# STM32N657 register map
File version: 1.0
CPU: CM55 r0p1, little endian, no MPU, FPU, vendor SysTick, 8 interrupt priority bits
Registers are 32-bit, read-write, reset 0x0 unless marked. A register's access mark holds for its fields unless they carry their own. Offsets are from the block's base; [hi:lo] are bit positions; 'fields as' and 'values as' point back to an identical list.

## LTDC — LCD-TFT display controller
Base 0x48001000
Same registers: LTDC_S 0x58001000
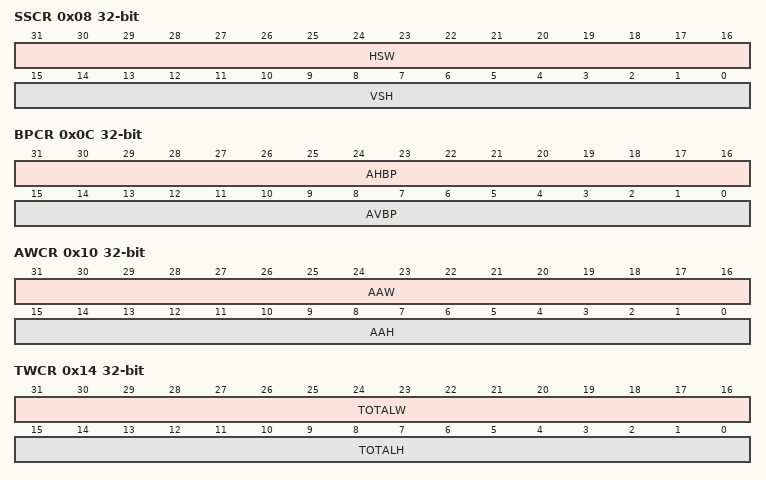
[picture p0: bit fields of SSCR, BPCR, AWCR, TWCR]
0x08 SSCR — LTDC synchronization size configuration register
  [31:16] HSW — horizontal synchronization width (in units of pixel clock period)
  [15:0] VSH — vertical synchronization height (in units of horizontal scan line)
0x0C BPCR — LTDC back porch configuration register
  [31:16] AHBP — accumulated horizontal back porch (in units of pixel clock period)
  [15:0] AVBP — accumulated Vertical back porch (in units of horizontal scan line)
0x10 AWCR — LTDC active width configuration register
  [31:16] AAW — accumulated active width (in units of pixel clock period)
  [15:0] AAH — accumulated active height (in units of horizontal scan line)
0x14 TWCR — LTDC total width configuration register
  [31:16] TOTALW — total width (in units of pixel clock period)
  [15:0] TOTALH — total height (in units of horizontal scan line)
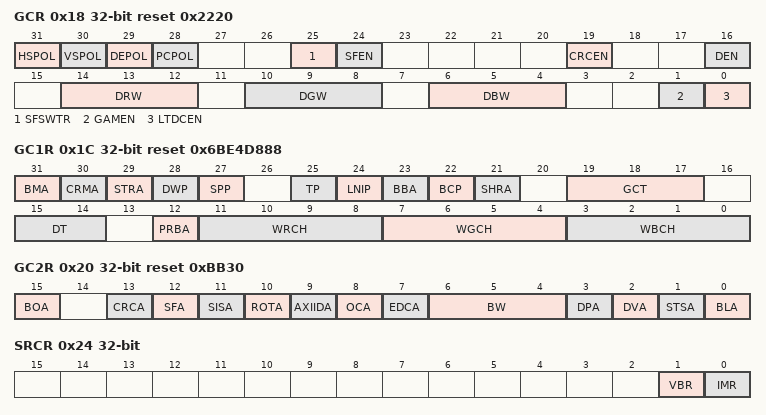
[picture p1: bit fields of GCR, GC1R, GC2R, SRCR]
0x18 GCR access per field reset 0x2220 — LTDC global control register
  [31] HSPOL rw — horizontal synchronization polarity
  [30] VSPOL rw — vertical synchronization polarity
  [29] DEPOL rw — blanking (no data/pixel) polarity
  [28] PCPOL rw — pixel clock polarity
  [25] SFSWTR wo — single-frame mode: software trigger
  [24] SFEN rw — single-frame mode: mode enable
  [19] CRCEN rw — CRC enable
  [16] DEN rw — dither enable
  [14:12] DRW ro — dither red width
  [10:8] DGW ro — dither green width
  [6:4] DBW ro — dither blue width
  [1] GAMEN rw — Gamma correction enable
  [0] LTDCEN rw — LTDC global enable
0x1C GC1R ro reset 0x6BE4D888 — LTDC global configuration 1 register
  [31] BMA — blind mode ability
  [30] CRMA — configuration reading mode ability
  [29] STRA — status register ability
  [28] DWP — dither width programmability
  [27] SPP — sync polarity programmability
  [25] TP — timing programmability
  [24] LNIP — line-IRQ: line position programmability
  [23] BBA — background blending ability
  [22] BCP — background color programmability (unique color blended as background)
  [21] SHRA — shadow registers ability
  [19:17] GCT — gamma correction technique implemented
  [15:14] DT — dithering technique implemented
  [12] PRBA — precise blending ability
  [11:8] WRCH — width of red channel output
  [7:4] WGCH — width of green channel output
  [3:0] WBCH — width of blue channel output
0x20 GC2R ro reset 0xBB30 — LTDC global configuration 2 register
  [15] BOA — blending order ability
  [13] CRCA — CRC ability
  [12] SFA — single frame mode ability
  [11] SISA — second interrupt set ability
  [10] ROTA — rotation support ability
  [9] AXIIDA — AXIID ability
  [8] OCA — output conversion ability (RGB to YCbCr)
  [7] EDCA — external display control ability
  [6:4] BW — bus width (log2 of number of bytes)
  [3] DPA — secondary RGB output port ability
  [2] DVA — dual-view ability
  [1] STSA — slave timings synchronization ability
  [0] BLA — background layer ability (pixels of background layer are read from memory)
0x24 SRCR — LTDC shadow reload configuration register
  [1] VBR — vertical blanking reload request
  [0] IMR — immediate reload trigger
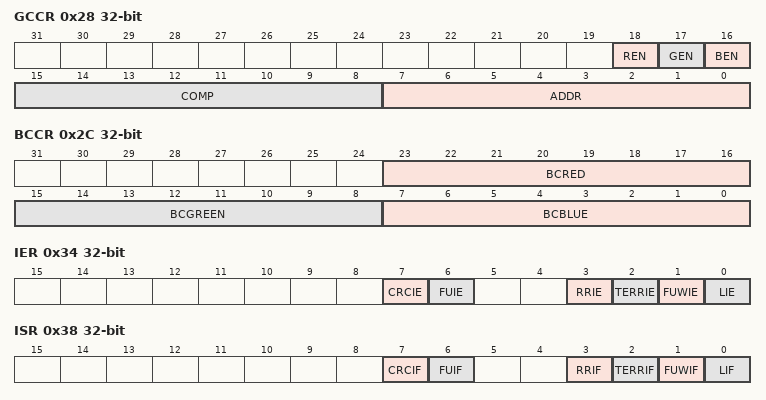
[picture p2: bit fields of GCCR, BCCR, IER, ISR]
0x28 GCCR wo — LTDC gamma correction configuration register
  [18] REN — write trigger to the red table
  [17] GEN — write trigger to the green table
  [16] BEN — write trigger to the blue table
  [15:8] COMP — color component to be written, in either (or all) the R,G,B tables
  [7:0] ADDR — address of the R,G,B table where the COMP component is written
0x2C BCCR — LTDC background color configuration register
  [23:16] BCRED — background color red value
  [15:8] BCGREEN — background color green value
  [7:0] BCBLUE — background color blue value
0x34 IER — LTDC interrupt enable register
  [7] CRCIE — CRC error interrupt enable
  [6] FUIE — FIFO underrun interrupt enable
  [3] RRIE — Register reload interrupt enable
  [2] TERRIE — Transfer Error interrupt enable
  [1] FUWIE — FIFO underrun warning interrupt enable
  [0] LIE — Line interrupt enable
0x38 ISR ro — LTDC interrupt status register
  [7] CRCIF — CRC error interrupt flag
  [6] FUIF — FIFO underrun interrupt flag
  [3] RRIF — Register reload interrupt flag
  [2] TERRIF — Transfer error interrupt flag
  [1] FUWIF — FIFO underrun warning interrupt flag
  [0] LIF — Line interrupt flag
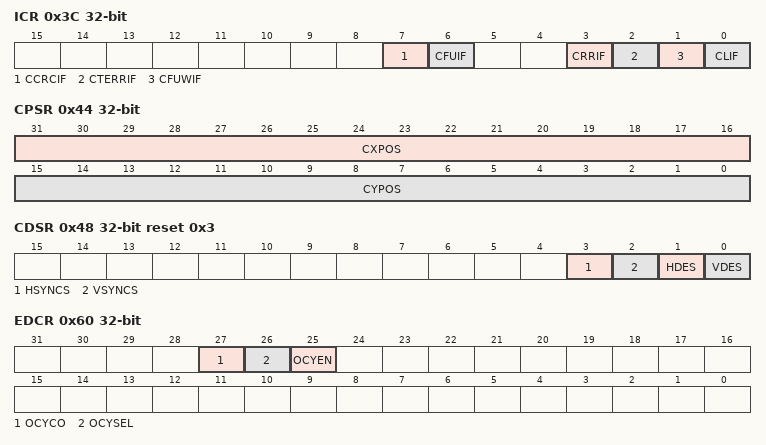
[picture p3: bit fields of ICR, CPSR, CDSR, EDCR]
0x3C ICR wo — LTDC interrupt clear register
  [7] CCRCIF — clears the CRC error interrupt flag
  [6] CFUIF — clears the FIFO underrun interrupt flag
  [3] CRRIF — clears register reload interrupt flag
  [2] CTERRIF — clears the transfer error interrupt flag
  [1] CFUWIF — clears the FIFO underrun warning interrupt flag
  [0] CLIF — clears the line interrupt flag
0x40 LIPCR — LTDC line interrupt position configuration register
  [15:0] LIPOS — line interrupt position
0x44 CPSR ro — LTDC current position status register
  [31:16] CXPOS — current X position
  [15:0] CYPOS — current Y position
0x48 CDSR ro reset 0x3 — LTDC current display status register
  [3] HSYNCS — horizontal synchronization display status
  [2] VSYNCS — vertical synchronization display status
  [1] HDES — horizontal data enable display status
  [0] VDES — vertical data enable display status
0x60 EDCR — LTDC external display control register
  [27] OCYCO — output conversion to YCbCr 422
  [26] OCYSEL — output conversion to YCbCr 422
  [25] OCYEN — output conversion to YCbCr 422 enable
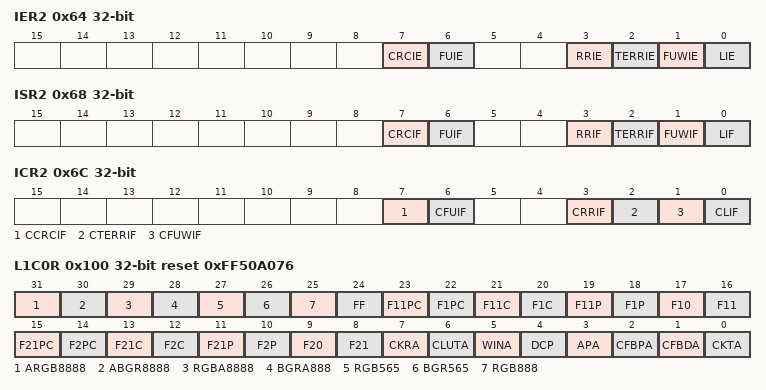
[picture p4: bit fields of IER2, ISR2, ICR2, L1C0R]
0x64 IER2 — LTDC interrupt enable register 2
  [7] CRCIE — CRC error interrupt enable
  [6] FUIE — FIFO underrun interrupt enable
  [3] RRIE — Register reload interrupt enable
  [2] TERRIE — Transfer error interrupt enable
  [1] FUWIE — FIFO underrun warning interrupt enable
  [0] LIE — Line interrupt enable
0x68 ISR2 ro — LTDC interrupt status register 2
  [7] CRCIF — CRC Error interrupt flag
  [6] FUIF — FIFO underrun interrupt flag
  [3] RRIF — Register reload interrupt flag
  [2] TERRIF — Transfer error interrupt flag
  [1] FUWIF — FIFO underrun warning interrupt flag
  [0] LIF — Line interrupt flag
0x6C ICR2 wo — LTDC interrupt clear register 2
  [7] CCRCIF — clears the CRC error interrupt flag
  [6] CFUIF — clears the FIFO underrun interrupt flag
  [3] CRRIF — clears register reload interrupt flag
  [2] CTERRIF — clears the Transfer Error interrupt flag
  [1] CFUWIF — clears the FIFO underrun warning interrupt flag
  [0] CLIF — clears the Line interrupt flag
0x70 LIPCR2 — LTDC line interrupt position configuration register 2
  [15:0] LIPOS — line interrupt position
0x78 ECRCR — LTDC expected CRC register
  [15:0] ECRC — expected CRC of frame
0x7C CCRCR ro — LTDC computed CRC register
  [15:0] CCRC — computed CRC of frame
0x90 FUTR reset 0x10 — LTDC FIFO underrun threshold register
  [15:0] THRE — threshold to trigger a FIFO underrun interrupt (per FIFO word, 64 bits)
0x100 L1C0R ro reset 0xFF50A076 — LTDC layerx configuration 0 register
  [31] ARGB8888 — pixel format, ability for argb8888
  [30] ABGR8888 — pixel format, ability for abgr8888
  [29] RGBA8888 — pixel format, ability for rgba8888
  [28] BGRA888 — pixel format, ability for bgra8888
  [27] RGB565 — pixel format, ability for rgb565
  [26] BGR565 — pixel format, ability for bgr565
  [25] RGB888 — pixel format, ability for rgb888
  [24] FF — flexible pixel format, ability
  [23] F11PC — blending factor 1, ability for: 1.0 - (pixel_alpha * constant_alpha)
  [22] F1PC — blending factor 1, ability for: pixel_alpha * constant_alpha
  [21] F11C — blending factor 1, ability for: 1.0 - constant_alpha
  [20] F1C — blending factor 1, ability for: constant_alpha
  [19] F11P — blending factor 1, ability for: 1.0 - pixel_alpha
  [18] F1P — blending factor 1, ability for: pixel_alpha
  [17] F10 — blending factor 1,ability for: 0.0
  [16] F11 — blending factor 1, ability for: 1.0
  [15] F21PC — blending factor 2, ability for: 1.0 - (pixel_alpha * constant_alpha)
  [14] F2PC — blending factor 2, ability for: pixel_alpha * constant_alpha
  [13] F21C — blending factor 2, ability for: 1.0 - constant_alpha
  [12] F2C — blending factor 2, ability for: constant_alpha
  [11] F21P — blending factor 2, ability for: 1.0 - pixel_alpha
  [10] F2P — blending factor 2, ability for: pixel_alpha
  [9] F20 — blending factor 2, ability for: 0.0
  [8] F21 — blending factor 2, ability for: 1.0
  [7] CKRA — color key replace ability
  [6] CLUTA — CLUT ability
  [5] WINA — windowing ability
  [4] DCP — default color programmability
  [3] APA — alpha plane ability
  [2] CFBPA — color frame buffer pitch ability
  [1] CFBDA — color frame buffer duplication ability
  [0] CKTA — color key transparency ability
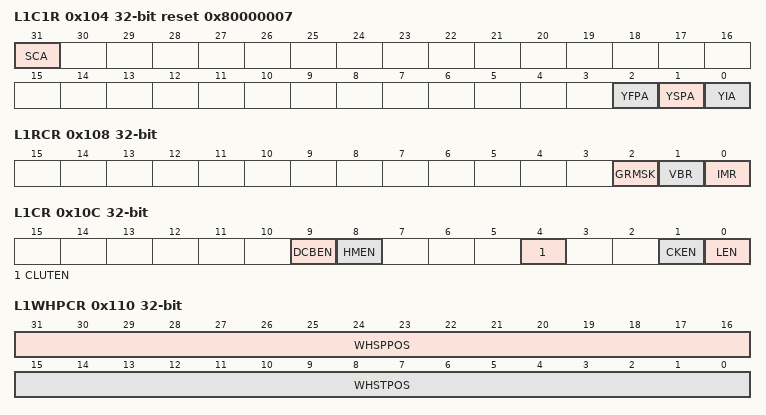
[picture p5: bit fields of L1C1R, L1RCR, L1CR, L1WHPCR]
0x104 L1C1R access per field reset 0x80000007 — LTDC layerx configuration 1 register
  [31] SCA rw — scaling ability for that layer
  [2] YFPA rw — YCbCr 420 full-planar ability for that layer
  [1] YSPA rw — YCbCr 420 semi-planar ability for that layer
  [0] YIA wo — YCbCr 422 interleaved ability for that layer
0x108 L1RCR access per field — LTDC layerx reload control register
  [2] GRMSK rw — shadow reload control, global (centralized) reload masked
  [1] VBR rw — vertical blanking reload request
  [0] IMR wo — immediate reload trigger
0x10C L1CR — LTDC layerx control register
  [9] DCBEN — default color blending enable
  [8] HMEN — horizontal mirroring enable
  [4] CLUTEN — color look-up table enable
  [1] CKEN — color keying enable
  [0] LEN — layer enable
0x110 L1WHPCR — LTDC layerx window horizontal position configuration register
  [31:16] WHSPPOS — window horizontal stop position
  [15:0] WHSTPOS — window horizontal start position
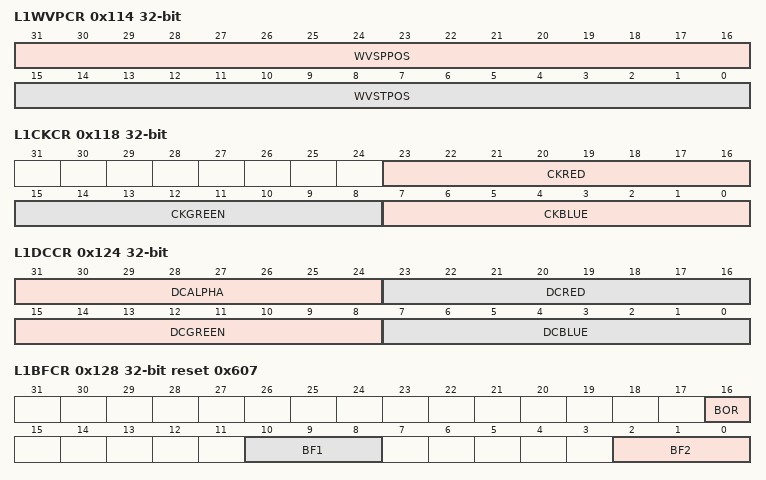
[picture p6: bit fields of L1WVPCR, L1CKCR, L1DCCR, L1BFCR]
0x114 L1WVPCR — LTDC layerx window vertical position configuration register
  [31:16] WVSPPOS — window vertical stop position
  [15:0] WVSTPOS — window vertical start position
0x118 L1CKCR — LTDC layerx color keying configuration register
  [23:16] CKRED — color key red value
  [15:8] CKGREEN — color key green value
  [7:0] CKBLUE — color key blue value
0x11C L1PFCR — LTDC layerx pixel format configuration register
  [2:0] PF — pixel format
0x120 L1CACR reset 0xFF — LTDC layerx constant alpha configuration register
  [7:0] CONSTA — constant alpha
0x124 L1DCCR — LTDC layerx default color configuration register
  [31:24] DCALPHA — default color alpha
  [23:16] DCRED — default color red
  [15:8] DCGREEN — default color green
  [7:0] DCBLUE — default color blue
0x128 L1BFCR reset 0x607 — LTDC layerx blending factors configuration register
  [16] BOR — blending order
  [10:8] BF1 — blending factor 1
  [2:0] BF2 — blending factor 2
0x12C L1BLCR — LTDC layerx burst length configuration register
  [7:0] BL — burst length
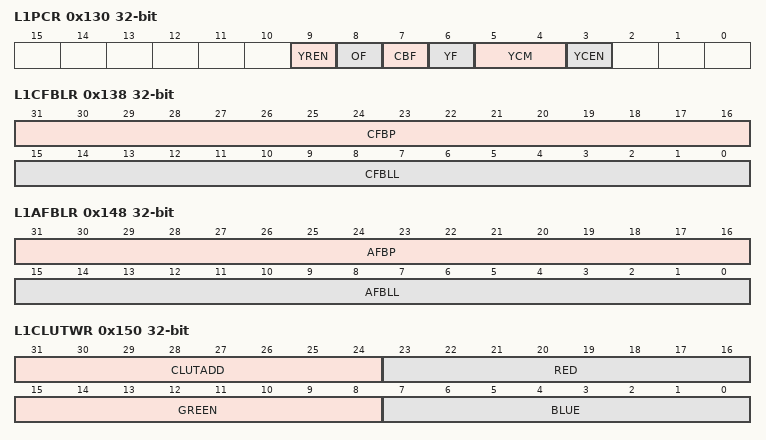
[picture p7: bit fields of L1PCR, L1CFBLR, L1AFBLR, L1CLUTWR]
0x130 L1PCR — LTDC layerx planar configuration register
  [9] YREN — Y rescale enable for the color dynamic range
  [8] OF — Odd pixel first
  [7] CBF — Cb component first
  [6] YF — Y component first
  [5:4] YCM — YCbCr conversion mode
  [3] YCEN — YCbCr-to-RGB conversion enable
0x134 L1CFBAR — LTDC layerx color frame buffer address register
  [31:0] CFBADD — color frame buffer start address
0x138 L1CFBLR — LTDC layerx color frame buffer length register
  [31:16] CFBP — color frame buffer pitch in bytes
  [15:0] CFBLL — color frame buffer line length
0x13C L1CFBLNR — LTDC layerx color frame buffer line number register
  [15:0] CFBLNBR — frame buffer line number
0x140 L1AFBA0R — LTDC layer1 auxiliary frame buffer address 0 register
  [31:0] AFBADD0 — frame buffer start address
0x144 L1AFBA1R — LTDC layer1 auxiliary frame buffer address 1 register
  [31:0] AFBADD1 — auxiliary frame buffer start address
0x148 L1AFBLR — LTDC layer1 auxiliary frame buffer length register
  [31:16] AFBP — auxiliary frame buffer pitch in bytes
  [15:0] AFBLL — auxiliary frame buffer line length
0x14C L1AFBLNR — LTDC layer1 auxiliary frame buffer line number register
  [15:0] AFBLNBR — auxiliary frame buffer line number
0x150 L1CLUTWR wo — LTDC layerx CLUT write register
  [31:24] CLUTADD — CLUT address
  [23:16] RED — red value
  [15:8] GREEN — green value
  [7:0] BLUE — blue value
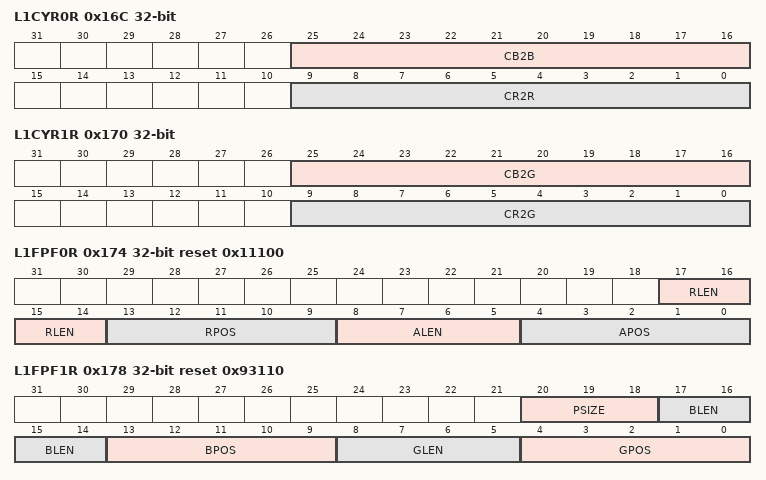
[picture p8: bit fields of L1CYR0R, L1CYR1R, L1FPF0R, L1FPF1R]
0x16C L1CYR0R — LTDC layerx conversion YCbCr RGB 0 register
  [25:16] CB2B — Cb-to-Blue coefficient, with bits 9:8 as positive integer and 7:0 as decimals.
  [9:0] CR2R — Cr-to-Red coefficient, with bits 9:8 as positive integer and 7:0 as decimals.
0x170 L1CYR1R — LTDC layerx conversion YCbCr RGB 1 register
  [25:16] CB2G — Cb-to-Green coefficient, with bits 9:8 as positive integer and 7:0 as decimals.
  [9:0] CR2G — Cr-to-Green coefficient, with bits 9:8 as positive integer and 7:0 as decimals.
0x174 L1FPF0R reset 0x11100 — LTDC layerx flexible pixel format 0 register
  [17:14] RLEN — Width of the Red component (in bits)
  [13:9] RPOS — Location of the Red component inside the pixel memory word (in bits)
  [8:5] ALEN — Width of the Alpha component (in bits)
  [4:0] APOS — Location of the Alpha component inside the pixel memory word (in bits)
0x178 L1FPF1R reset 0x93110 — LTDC layerx flexible pixel format 1 register
  [20:18] PSIZE — Pixel size (in bytes)
  [17:14] BLEN — Width of the Blue component (in bits)
  [13:9] BPOS — Location of the Blue component inside the pixel memory word (in bits)
  [8:5] GLEN — Width of the Green component (in bits)
  [4:0] GPOS — Location of the Green component inside the pixel memory word (in bits)
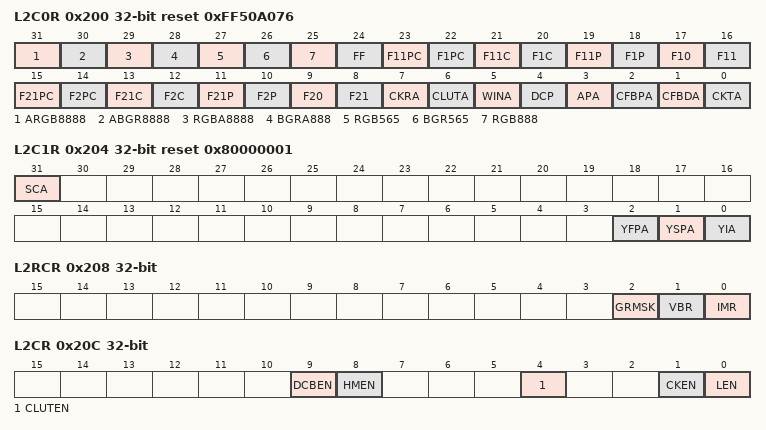
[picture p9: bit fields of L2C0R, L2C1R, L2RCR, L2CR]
0x200 L2C0R ro reset 0xFF50A076 — LTDC layerx configuration 0 register
  fields as L1C0R
0x204 L2C1R access per field reset 0x80000001 — LTDC layerx configuration 1 register
  fields as L1C1R
0x208 L2RCR access per field — LTDC layerx reload control register
  fields as L1RCR
0x20C L2CR — LTDC layerx control register
  fields as L1CR
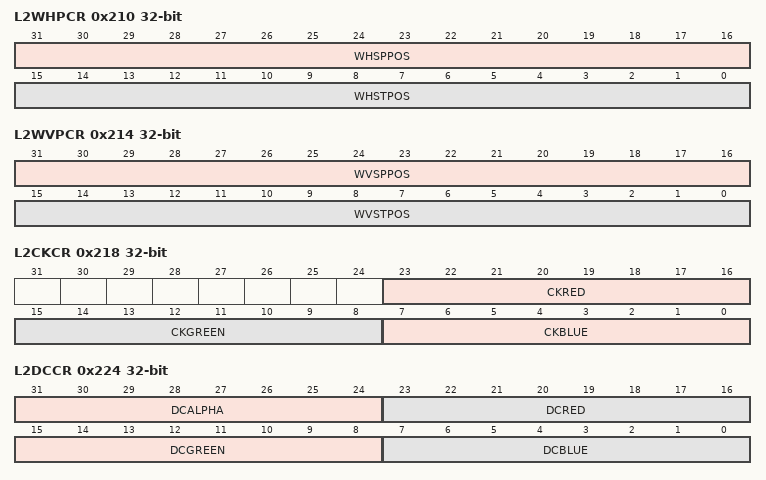
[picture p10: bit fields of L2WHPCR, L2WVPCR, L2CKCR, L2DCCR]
0x210 L2WHPCR — LTDC layerx window horizontal position configuration register
  fields as L1WHPCR
0x214 L2WVPCR — LTDC layerx window vertical position configuration register
  fields as L1WVPCR
0x218 L2CKCR — LTDC layerx color keying configuration register
  fields as L1CKCR
0x21C L2PFCR — LTDC layerx pixel format configuration register
  [2:0] PF — pixel format
0x220 L2CACR reset 0xFF — LTDC layerx constant alpha configuration register
  [7:0] CONSTA — constant alpha
0x224 L2DCCR — LTDC layerx default color configuration register
  fields as L1DCCR
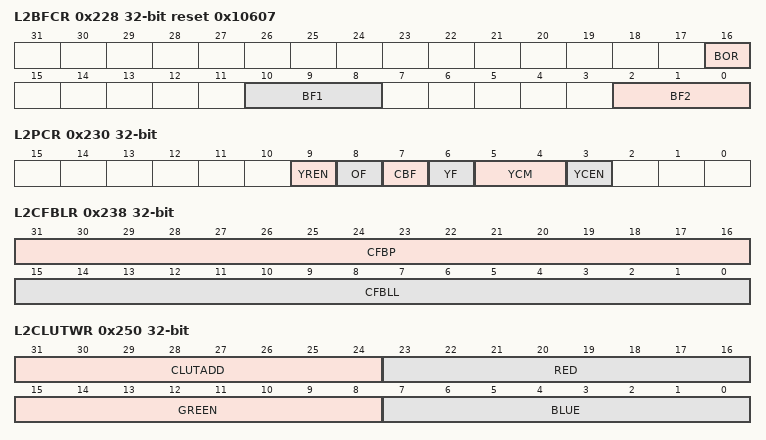
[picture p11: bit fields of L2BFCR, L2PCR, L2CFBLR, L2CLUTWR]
0x228 L2BFCR reset 0x10607 — LTDC layerx blending factors configuration register
  fields as L1BFCR
0x22C L2BLCR — LTDC layerx burst length configuration register
  [7:0] BL — burst length
0x230 L2PCR — LTDC layerx planar configuration register
  fields as L1PCR
0x234 L2CFBAR — LTDC layerx color frame buffer address register
  [31:0] CFBADD — color frame buffer start address
0x238 L2CFBLR — LTDC layerx color frame buffer length register
  fields as L1CFBLR
0x23C L2CFBLNR — LTDC layerx color frame buffer line number register
  [15:0] CFBLNBR — frame buffer line number
0x250 L2CLUTWR wo — LTDC layerx CLUT write register
  fields as L1CLUTWR
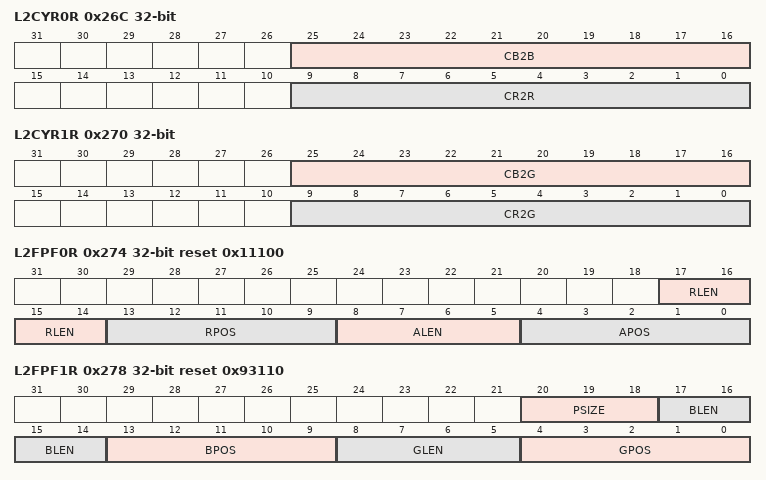
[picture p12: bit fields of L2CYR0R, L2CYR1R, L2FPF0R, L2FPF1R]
0x26C L2CYR0R — LTDC layerx conversion YCbCr RGB 0 register
  fields as L1CYR0R
0x270 L2CYR1R — LTDC layerx conversion YCbCr RGB 1 register
  fields as L1CYR1R
0x274 L2FPF0R reset 0x11100 — LTDC layerx flexible pixel format 0 register
  fields as L1FPF0R
0x278 L2FPF1R reset 0x93110 — LTDC layerx flexible pixel format 1 register
  fields as L1FPF1R
